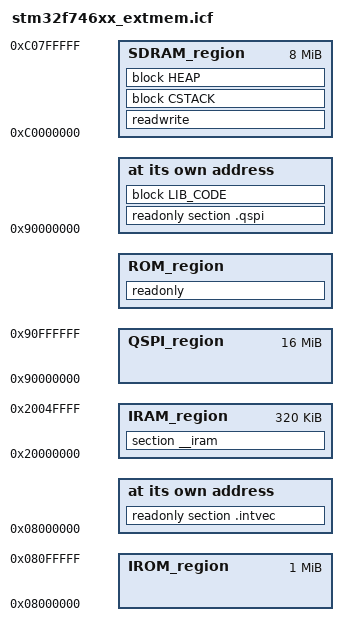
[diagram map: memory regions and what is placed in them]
/*###ICF### Section handled by ICF editor, don't touch! ****/
/*-Editor annotation file-*/
/* IcfEditorFile="$TOOLKIT_DIR$\config\ide\IcfEditor\cortex_v1_0.xml" */
/*-Specials-*/
define symbol __ICFEDIT_intvec_start__ = 0x08000000;
/*-Memory Regions-*/
define symbol __ICFEDIT_region_IROM_start__  = 0x08000000;
define symbol __ICFEDIT_region_IROM_end__    = 0x080FFFFF;
define symbol __ICFEDIT_region_SDRAM_start__ = 0xC0000000;
define symbol __ICFEDIT_region_SDRAM_end__   = 0xC07FFFFF;
define symbol __ICFEDIT_region_IRAM_start__  = 0x20000000;
define symbol __ICFEDIT_region_IRAM_end__    = 0x2004FFFF;
define symbol __ICFEDIT_region_QSPI_start__  = 0x90000000;
define symbol __ICFEDIT_region_QSPI_end__    = 0x90FFFFFF;

/*-Sizes-*/
define symbol __ICFEDIT_size_cstack__ = 0x200;
define symbol __ICFEDIT_size_heap__   = 0x530000;
/**** End of ICF editor section. ###ICF###*/


define memory mem with size = 4G;
define region IROM_region     = mem:[from __ICFEDIT_region_IROM_start__  to __ICFEDIT_region_IROM_end__];
define region IRAM_region     = mem:[from __ICFEDIT_region_IRAM_start__ to __ICFEDIT_region_IRAM_end__];
define region QSPI_region     = mem:[from __ICFEDIT_region_QSPI_start__ to __ICFEDIT_region_QSPI_end__];
define region ROM_region      = IROM_region-QSPI_region;
define region SDRAM_region    = mem:[from __ICFEDIT_region_SDRAM_start__  to __ICFEDIT_region_SDRAM_end__];

define block CSTACK    with alignment = 8, size = __ICFEDIT_size_cstack__   { };
define block HEAP      with alignment = 8, size = __ICFEDIT_size_heap__     { };

initialize by copy { readwrite };
do not initialize  { section .noinit };

place at address mem:__ICFEDIT_intvec_start__ { readonly section .intvec };

define block LIB_CODE
{
    readonly object libavcodec.a,
    readonly object libavdevice.a,
    readonly object libavfilter.a,
    readonly object libavformat.a,
    readonly object libavutil.a,
    readonly object libswresample.a,
    readonly object liblibswscale.a
};

place in ROM_region   { readonly };
place in SDRAM_region { readwrite, block CSTACK, block HEAP };
place in IRAM_region  { section __iram };

place at address mem:__ICFEDIT_region_QSPI_start__ { readonly section .qspi, block LIB_CODE };

/*place in QSPI_region  { section .qspi, last block LIB_CODE };*/
